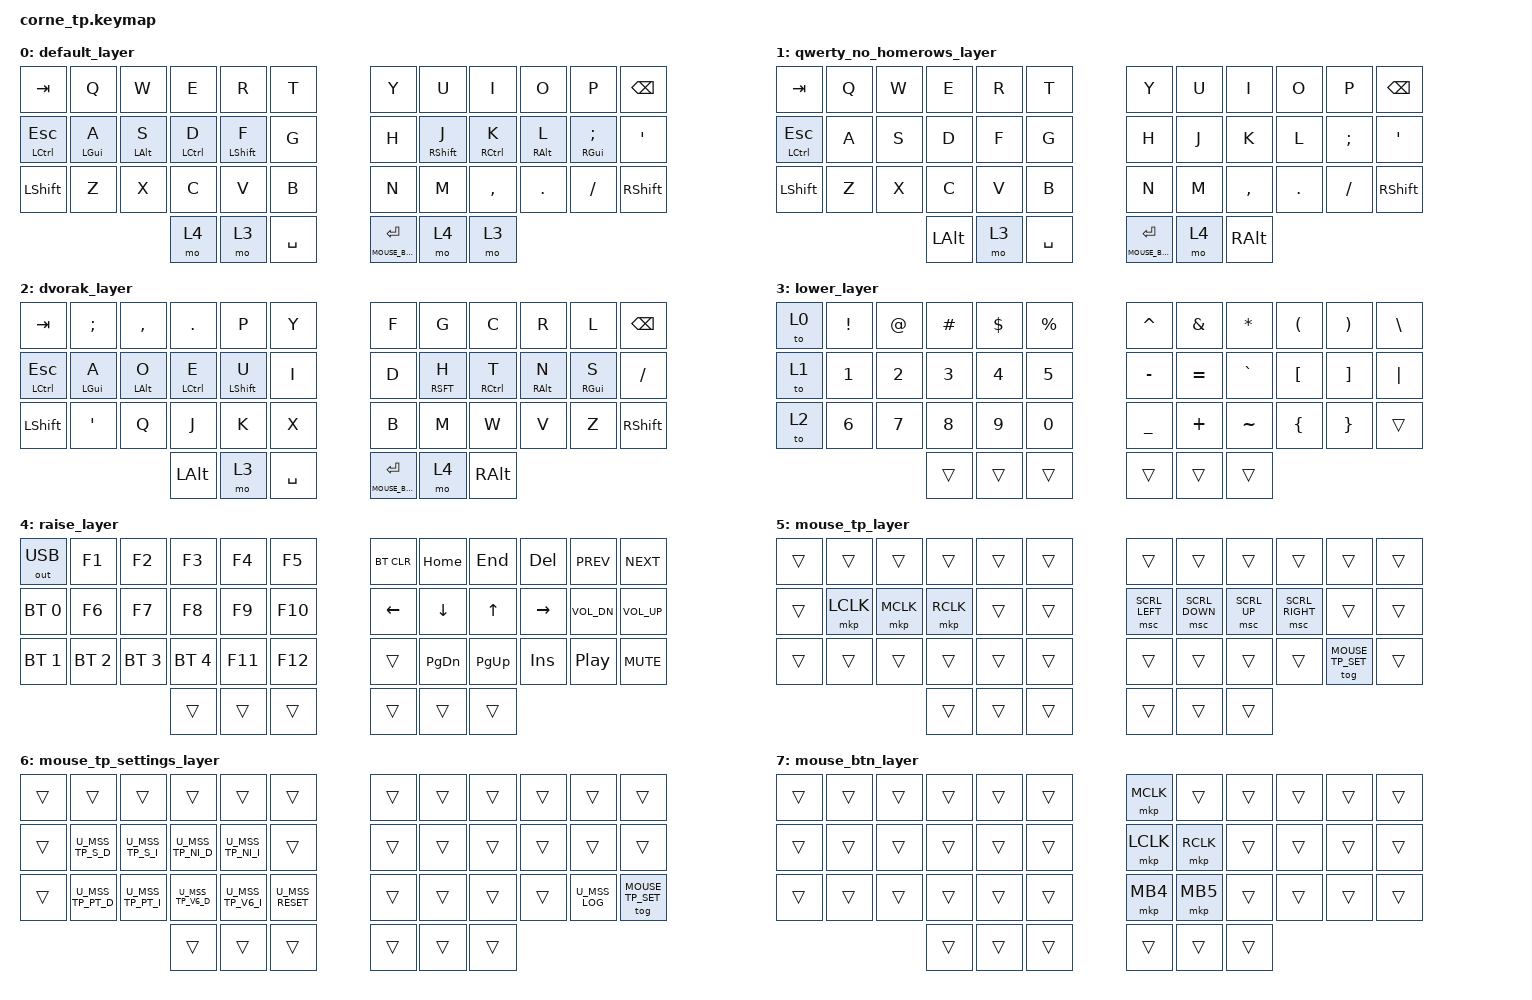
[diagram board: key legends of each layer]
/*
 * Copyright (c) 2020 The ZMK Contributors
 *
 * SPDX-License-Identifier: MIT
 */

#include <behaviors.dtsi>
#include <dt-bindings/zmk/keys.h>
#include <dt-bindings/zmk/bt.h>
#include <dt-bindings/zmk/outputs.h>

#define MOUSE_TP 5
#define MOUSE_TP_SET 6
#define MOUSE_BTN 7
#define HAS_MOUSE_TP
#include "include/mouse_tp.dtsi"

/ {
        behaviors {
                hm: homerow_mods {
                        compatible = "zmk,behavior-hold-tap";
                        label = "HOMEROW_MODS";
                        #binding-cells = <2>;
                        tapping-term-ms = <180>;
                        quick-tap-ms = <0>;
                        flavor = "tap-preferred";
                        bindings = <&kp>, <&kp>;
                };
        };

        keymap {
                compatible = "zmk,keymap";

                default_layer {
                        bindings = <
   &kp TAB       &kp Q      &kp W      &kp E       &kp R       &kp T         &kp Y   &kp U        &kp I       &kp O      &kp P         &kp BSPC
   &hm LCTRL ESC &hm LGUI A &hm LALT S &hm LCTRL D &hm LSHFT F &kp G         &kp H   &hm RSHFT J  &hm RCTRL K &hm RALT L &hm RGUI SEMI &kp SQT
   &kp LSHFT     &kp Z      &kp X      &kp C       &kp V       &kp B         &kp N   &kp M        &kp COMMA   &kp DOT    &kp FSLH      &kp RSHFT
                                       &mo 4       &mo 3       &kp SPACE     &lt MOUSE_BTN RET &mo 4        &mo 3
                        >;
                };

                qwerty_no_homerows_layer {
  bindings = <
        &kp TAB       &kp Q &kp W &kp E    &kp R &kp T        &kp Y   &kp U &kp I     &kp O   &kp P    &kp BSPC
        &hm LCTRL ESC &kp A &kp S &kp D    &kp F &kp G        &kp H   &kp J &kp K     &kp L   &kp SEMI &kp SQT
        &kp LSHFT     &kp Z &kp X &kp C    &kp V &kp B        &kp N   &kp M &kp COMMA &kp DOT &kp FSLH &kp RSHFT
                                  &kp LALT &mo 3 &kp SPACE    &lt MOUSE_BTN RET &mo 4 &kp RALT
    >;
                };

                dvorak_layer {
    bindings = <
        &kp TAB       &kp SEMI   &kp COMMA  &kp DOT     &kp P       &kp Y         &kp F   &kp G      &kp C       &kp R      &kp L      &kp BSPC
        &hm LCTRL ESC &hm LGUI A &hm LALT O &hm LCTRL E &hm LSHFT U &kp I         &kp D   &hm RSFT H &hm RCTRL T &hm RALT N &hm RGUI S &kp FSLH
        &kp LSHFT     &kp SQT    &kp Q      &kp J       &kp K       &kp X         &kp B   &kp M      &kp W       &kp V      &kp Z      &kp RSHFT
                                            &kp LALT    &mo 3       &kp SPACE     &lt MOUSE_BTN RET &mo 4      &kp RALT
    >;
                };

                lower_layer {
  bindings = <
    &to 0 &kp EXCL &kp AT &kp HASH &kp DLLR &kp PRCNT      &kp CARET &kp AMPS  &kp ASTRK &kp LPAR &kp RPAR &kp BSLH
    &to 1 &kp N1   &kp N2 &kp N3   &kp N4   &kp N5         &kp MINUS &kp EQUAL &kp GRAVE &kp LBKT &kp RBKT &kp PIPE
    &to 2 &kp N6   &kp N7 &kp N8   &kp N9   &kp N0         &kp UNDER &kp PLUS  &kp TILDE &kp LBRC &kp RBRC &trans
                     &trans   &trans   &trans         &trans    &trans    &trans
  >;
                };

                raise_layer {
    bindings = <
        &out OUT_USB &kp F1       &kp F2       &kp F3       &kp F4  &kp F5       &bt BT_CLR &kp HOME  &kp END   &kp DEL   &kp C_PREV   &kp C_NEXT
        &bt BT_SEL 0 &kp F6       &kp F7       &kp F8       &kp F9  &kp F10      &kp LEFT   &kp DOWN  &kp UP    &kp RIGHT &kp C_VOL_DN &kp C_VOL_UP
        &bt BT_SEL 1 &bt BT_SEL 2 &bt BT_SEL 3 &bt BT_SEL 4 &kp F11 &kp F12      &trans     &kp PG_DN &kp PG_UP &kp INS   &kp C_PP     &kp C_MUTE
                                               &trans       &trans  &trans       &trans     &trans    &trans
    >;
                };

                mouse_tp_layer {
                        bindings = <
    &trans     &trans     &trans     &trans     &trans       &trans      &trans        &trans        &trans        &trans        &trans        &trans
    &trans     &mkp LCLK  &mkp MCLK  &mkp RCLK  &trans       &trans      &msc SCRL_LEFT &msc SCRL_DOWN &msc SCRL_UP  &msc SCRL_RIGHT &trans      &trans
    &trans     &trans     &trans     &trans     &trans       &trans      &trans        &trans        &trans        &trans        &tog MOUSE_TP_SET &trans
                                              &trans       &trans       &trans      &trans        &trans        &trans
                        >;
                };

                mouse_tp_settings_layer {
                        bindings = <
    &trans      &trans       &trans       &trans       &trans       &trans       &trans       &trans       &trans       &trans      &trans      &trans
    &trans      U_MSS_TP_S_D U_MSS_TP_S_I U_MSS_TP_NI_D U_MSS_TP_NI_I &trans      &trans       &trans       &trans       &trans      &trans      &trans
    &trans      U_MSS_TP_PT_D U_MSS_TP_PT_I U_MSS_TP_V6_D U_MSS_TP_V6_I U_MSS_RESET &trans      &trans       &trans       &trans      U_MSS_LOG  &tog MOUSE_TP_SET
                                                   &trans        &trans        &trans       &trans       &trans      &trans
                        >;
                };

                mouse_btn_layer {
                        bindings = <
    &trans    &trans    &trans    &trans    &trans    &trans    &mkp MCLK &trans    &trans    &trans    &trans    &trans
    &trans    &trans    &trans    &trans    &trans    &trans    &mkp LCLK &mkp RCLK &trans    &trans    &trans    &trans
    &trans    &trans    &trans    &trans    &trans    &trans    &mkp MB4  &mkp MB5  &trans    &trans    &trans    &trans
                                         &trans    &trans    &trans    &trans    &trans    &trans
                        >;
                };
        };
};
